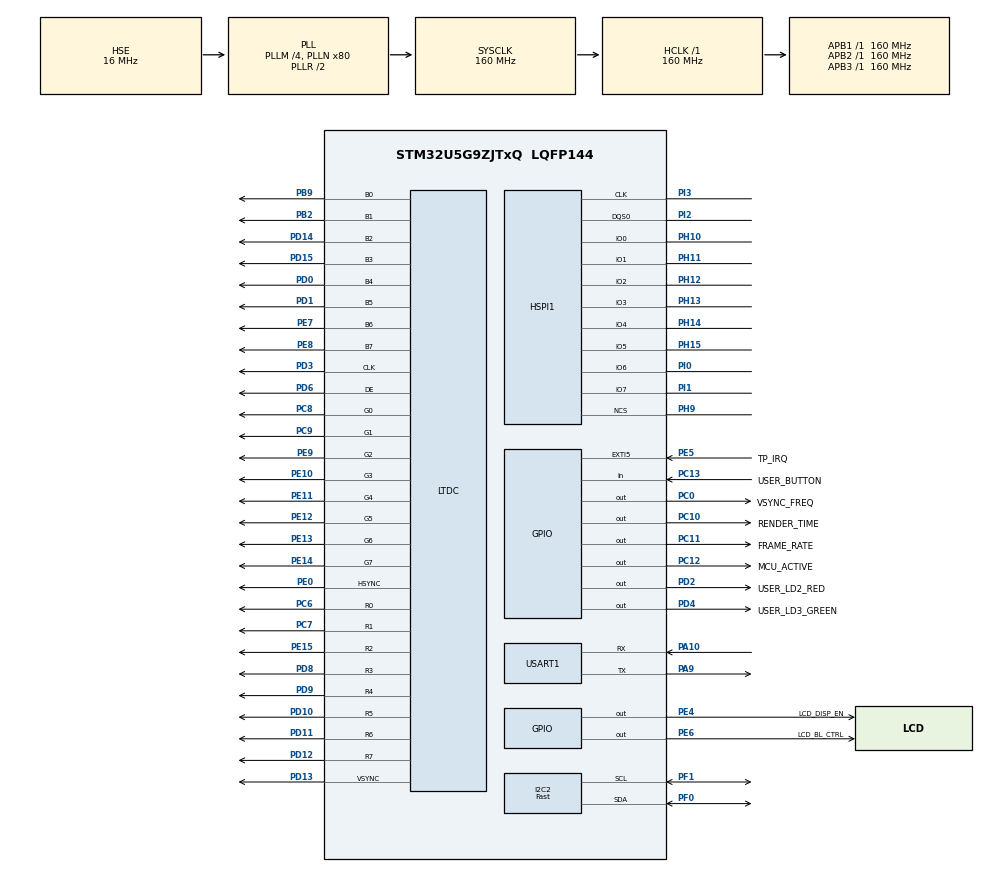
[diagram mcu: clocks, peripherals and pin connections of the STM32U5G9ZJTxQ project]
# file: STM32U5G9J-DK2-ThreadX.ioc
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CORTEX_M33_NS.userName=CORTEX_M33
DCACHE1.DCACHE_Read_Burst_Type=DCACHE_READ_BURST_INCR
DCACHE2.DCACHE_Read_Burst_Type=DCACHE_READ_BURST_INCR
DMA2D.ColorMode=DMA2D_OUTPUT_RGB888
DMA2D.Mode=DMA2D_R2M
GPDMA1.DATAALIGNEMENT_GPDMACH0=DMA_DATA_PACK
GPDMA1.DATAHANDLING_GPDMACH0=ENABLE
GPDMA1.DATAHANDLING_GPDMACH1=NONE
GPDMA1.DESTBURSTLENGTH_GPDMACH0=8
GPDMA1.DESTBURSTLENGTH_GPDMACH1=8
GPDMA1.DESTDATAWIDTH_GPDMACH0=DMA_DEST_DATAWIDTH_WORD
GPDMA1.DESTDATAWIDTH_GPDMACH1=DMA_DEST_DATAWIDTH_WORD
GPDMA1.DESTINC_GPDMACH1=DMA_DINC_INCREMENTED
GPDMA1.DIRECTION_GPDMACH0=DMA_MEMORY_TO_PERIPH
GPDMA1.IPHANDLE_GPDMACH0-SIMPLEREQUEST_GPDMACH0=__NULL
GPDMA1.IPHANDLE_GPDMACH1-SIMPLEREQUEST_GPDMACH1=__NULL
GPDMA1.PRIORITY_GPDMACH0=DMA_HIGH_PRIORITY
GPDMA1.PRIORITY_GPDMACH1=DMA_HIGH_PRIORITY
GPDMA1.REQUEST_GPDMACH0=GPDMA1_REQUEST_JPEG_RX
GPDMA1.REQUEST_GPDMACH1=GPDMA1_REQUEST_JPEG_TX
GPDMA1.SRCBURSTLENGTH_GPDMACH0=8
GPDMA1.SRCBURSTLENGTH_GPDMACH1=8
GPDMA1.SRCDATAWIDTH_GPDMACH1=DMA_SRC_DATAWIDTH_WORD
GPDMA1.SRCINC_GPDMACH0=DMA_SINC_INCREMENTED
GPDMA1.TRANSFERALLOCATEDPORTDEST_GPDMACH1=DMA_DEST_ALLOCATED_PORT1
GPDMA1.TRANSFERALLOCATEDPORTSRC_GPDMACH0=DMA_SRC_ALLOCATED_PORT1
HSPI1.ChipSelectHighTimeCycle=2
HSPI1.ClockPrescaler=0
HSPI1.DeviceType=SPI_DEVICE_FLASH
HSPI1.FifoThresholdByte=4
HSPI1.MemorySize=HAL_XSPI_SIZE_1GB
HSPI1.MemoryType=HAL_XSPI_MEMTYPE_MACRONIX
I2C2.I2C_Speed_Mode=I2C_Fast
I2C2.Timing=0x00F07BFF
JPEG.JPEG_RGB_FORMAT=JPEG_RGB565
JPEG.USE_JPEG_ENCODER=0
LTDC.ActiveW=800
LTDC.Alpha_L0=255
LTDC.FBStartAdress_L0=0x20000000
LTDC.HBP=8
LTDC.HFP=8
LTDC.HSync=5
LTDC.ImageHeight_L0=480
LTDC.ImageWidth_L0=800
LTDC.Layers=0
LTDC.PixelFormat_L0=LTDC_PIXEL_FORMAT_RGB565
LTDC.VBP=8
LTDC.VFP=14
LTDC.VSync=5
LTDC.WindowX1_L0=800
LTDC.WindowY1_L0=480
Mcu.Family=STM32U5
Mcu.Name=STM32U5G9ZJTxQ
Mcu.Package=LQFP144
NVIC.DMA2D_IRQn=true\:0\:0\:false\:false\:true\:true\:true\:true
NVIC.EXTI5_IRQn=true\:0\:0\:false\:false\:true\:true\:true\:true
NVIC.GPDMA1_Channel0_IRQn=true\:0\:0\:false\:false\:true\:false\:true\:true
NVIC.GPDMA1_Channel1_IRQn=true\:0\:0\:false\:false\:true\:false\:true\:true
NVIC.GPU2D_ER_IRQn=true\:0\:0\:false\:false\:true\:true\:true\:true
NVIC.GPU2D_IRQn=true\:0\:0\:false\:false\:true\:true\:true\:true
NVIC.HSPI1_IRQn=true\:0\:0\:false\:false\:true\:true\:true\:true
NVIC.JPEG_IRQn=true\:7\:0\:true\:false\:true\:true\:true\:true
NVIC.LTDC_ER_IRQn=true\:0\:0\:false\:false\:true\:true\:true\:true
NVIC.LTDC_IRQn=true\:0\:0\:false\:false\:true\:true\:true\:true
NVIC.PriorityGroup=NVIC_PRIORITYGROUP_4
NVIC.TIM6_IRQn=true\:15\:0\:true\:false\:true\:false\:true\:true
NVIC.TimeBase=TIM6_IRQn
NVIC.TimeBaseIP=TIM6
PA10.Mode=Asynchronous
PA10.Signal=USART1_RX
PA9.Mode=Asynchronous
PA9.Signal=USART1_TX
PB2.Mode=RGB888
PB2.Signal=LTDC_B1
PB9.Mode=RGB888
PB9.Signal=LTDC_B0
PC0.GPIO_Label=VSYNC_FREQ
PC0.GPIO_Speed=GPIO_SPEED_FREQ_MEDIUM
PC0.Signal=GPIO_Output
PC10.GPIO_Label=RENDER_TIME
PC10.GPIO_Speed=GPIO_SPEED_FREQ_MEDIUM
PC10.Signal=GPIO_Output
PC11.GPIO_Label=FRAME_RATE
PC11.GPIO_Speed=GPIO_SPEED_FREQ_MEDIUM
PC11.Signal=GPIO_Output
PC12.GPIO_Label=MCU_ACTIVE
PC12.GPIO_Speed=GPIO_SPEED_FREQ_MEDIUM
PC12.Signal=GPIO_Output
PC13.GPIO_Label=USER_BUTTON
PC13.GPIO_PuPd=GPIO_PULLDOWN
PC13.Signal=GPIO_Input
PC6.Mode=RGB888
PC6.Signal=LTDC_R0
PC7.Mode=RGB888
PC7.Signal=LTDC_R1
PC8.Mode=RGB888
PC8.Signal=LTDC_G0
PC9.Mode=RGB888
PC9.Signal=LTDC_G1
PD0.Mode=RGB888
PD0.Signal=LTDC_B4
PD1.Mode=RGB888
PD1.Signal=LTDC_B5
PD10.Mode=RGB888
PD10.Signal=LTDC_R5
PD11.Mode=RGB888
PD11.Signal=LTDC_R6
PD12.Mode=RGB888
PD12.Signal=LTDC_R7
PD13.GPIO_Mode=GPIO_MODE_AF_PP
PD13.GPIO_Speed=GPIO_SPEED_FREQ_LOW
PD13.Mode=RGB888
PD13.Signal=LTDC_VSYNC
PD14.Mode=RGB888
PD14.Signal=LTDC_B2
PD15.Mode=RGB888
PD15.Signal=LTDC_B3
PD2.GPIO_Label=USER_LD2_RED
PD2.GPIO_ModeDefaultOutputPP=GPIO_MODE_OUTPUT_OD
PD2.GPIO_PuPd=GPIO_NOPULL
PD2.GPIO_Speed=GPIO_SPEED_FREQ_MEDIUM
PD2.PinState=GPIO_PIN_SET
PD2.Signal=GPIO_Output
PD3.GPIO_Speed=GPIO_SPEED_FREQ_LOW
PD3.Mode=RGB888
PD3.Signal=LTDC_CLK
PD4.GPIO_Label=USER_LD3_GREEN
PD4.GPIO_ModeDefaultOutputPP=GPIO_MODE_OUTPUT_OD
PD4.GPIO_PuPd=GPIO_NOPULL
PD4.GPIO_Speed=GPIO_SPEED_FREQ_MEDIUM
PD4.PinState=GPIO_PIN_SET
PD4.Signal=GPIO_Output
PD6.Mode=RGB888
PD6.Signal=LTDC_DE
PD8.Mode=RGB888
PD8.Signal=LTDC_R3
PD9.Mode=RGB888
PD9.Signal=LTDC_R4
PE0.GPIO_Speed=GPIO_SPEED_FREQ_LOW
PE0.Mode=RGB888
PE0.Signal=LTDC_HSYNC
PE10.Mode=RGB888
PE10.Signal=LTDC_G3
PE11.Mode=RGB888
PE11.Signal=LTDC_G4
PE12.Mode=RGB888
PE12.Signal=LTDC_G5
PE13.Mode=RGB888
PE13.Signal=LTDC_G6
PE14.Mode=RGB888
PE14.Signal=LTDC_G7
PE15.Mode=RGB888
PE15.Signal=LTDC_R2
PE4.GPIO_Label=LCD_DISP_EN
PE4.PinState=GPIO_PIN_SET
PE4.Signal=GPIO_Output
PE5.GPIO_Label=TP_IRQ
PE5.GPIO_ModeDefaultEXTI=GPIO_MODE_IT_FALLING
PE5.GPIO_PuPd=GPIO_PULLUP
PE5.Signal=GPXTI5
PE6.GPIO_Label=LCD_BL_CTRL
PE6.GPIO_ModeDefaultOutputPP=GPIO_MODE_OUTPUT_OD
PE6.GPIO_PuPd=GPIO_NOPULL
PE6.PinState=GPIO_PIN_SET
PE6.Signal=GPIO_Output
PE7.Mode=RGB888
PE7.Signal=LTDC_B6
PE8.Mode=RGB888
PE8.Signal=LTDC_B7
PE9.Mode=RGB888
PE9.Signal=LTDC_G2
PF0.Mode=I2C
PF0.Signal=I2C2_SDA
PF1.Mode=I2C
PF1.Signal=I2C2_SCL
PH0-OSC_IN\ (PH0).Mode=HSE-External-Oscillator
PH0-OSC_IN\ (PH0).Signal=RCC_OSC_IN
PH1-OSC_OUT\ (PH1).Mode=HSE-External-Oscillator
PH1-OSC_OUT\ (PH1).Signal=RCC_OSC_OUT
PH10.Mode=octo_mode
PH10.Signal=HSPI1_IO0
PH11.Mode=octo_mode
PH11.Signal=HSPI1_IO1
PH12.Mode=octo_mode
PH12.Signal=HSPI1_IO2
PH13.Mode=octo_mode
PH13.Signal=HSPI1_IO3
PH14.Mode=octo_mode
PH14.Signal=HSPI1_IO4
PH15.Mode=octo_mode
PH15.Signal=HSPI1_IO5
PH9.Mode=octo_mode
PH9.Signal=HSPI1_NCS
PI0.Mode=octo_mode
PI0.Signal=HSPI1_IO6
PI1.Mode=octo_mode
PI1.Signal=HSPI1_IO7
PI2.Mode=octo_mode
PI2.Signal=HSPI1_DQS0
PI3.Mode=octo_mode
PI3.Signal=HSPI1_CLK
PWR.PowerMode=PWR_SMPS_SUPPLY
ProjectManager.HeapSize=0x1000
ProjectManager.StackSize=0x1000
ProjectManager.TargetToolchain=STM32CubeIDE
RCC.ADCFreq_Value=16000000
RCC.AHBFreq_Value=160000000
RCC.APB1Freq_Value=160000000
RCC.APB1TimFreq_Value=160000000
RCC.APB2Freq_Value=160000000
RCC.APB2TimFreq_Value=160000000
RCC.APB3Freq_Value=160000000
RCC.CortexFreq_Value=160000000
RCC.DSICLockSelection=RCC_DSICLKSOURCE_PLL3
RCC.EPOD_VALUE=16000000
RCC.HCLKFreq_Value=160000000
RCC.HSE_VALUE=16000000
RCC.HSI48_VALUE=48000000
RCC.HSI_VALUE=16000000
RCC.HSPICLockSelection=RCC_HSPICLKSOURCE_PLL2
RCC.LSE_VALUE=32768
RCC.LSIDIV_VALUE=32000
RCC.LTDCCLockSelection=RCC_LTDCCLKSOURCE_PLL3
RCC.MSI_VALUE=4000000
RCC.PLL2M=4
RCC.PLL2N=66
RCC.PLL2Source=RCC_PLLSOURCE_HSE
RCC.PLL3M=4
RCC.PLL3N=125
RCC.PLL3P=8
RCC.PLL3R=20
RCC.PLL3Source=RCC_PLLSOURCE_HSE
RCC.PLLDSIIDF=DSI_PLL_IN_DIV4
RCC.PLLDSINDIV=125
RCC.PLLDSIODF=DSI_PLL_OUT_DIV2
RCC.PLLM=4
RCC.PLLN=80
RCC.PLLSourceVirtual=RCC_PLLSOURCE_HSE
RCC.SYSCLKFreq_VALUE=160000000
RCC.SYSCLKSource=RCC_SYSCLKSOURCE_PLLCLK
RCC.VCOOutputFreq_Value=320000000
STMicroelectronics.X-CUBE-FREERTOS.1.0.1.configENABLE_FPU=1
STMicroelectronics.X-CUBE-FREERTOS.1.0.1.configTOTAL_HEAP_SIZE=80000
STMicroelectronics.X-CUBE-FREERTOS.1.0.1.configUSE_APPLICATION_TASK_TAG=1
STMicroelectronics.X-CUBE-FREERTOS.1.0.1.configUSE_IDLE_HOOK=1
STMicroelectronics.X-CUBE-TOUCHGFX.4.23.2.tgfx_buffering_strategy=Double
STMicroelectronics.X-CUBE-TOUCHGFX.4.23.2.tgfx_display_interface=disp_ltdc
STMicroelectronics.X-CUBE-TOUCHGFX.4.23.2.tgfx_hardware_accelerator=dma_2d
STMicroelectronics.X-CUBE-TOUCHGFX.4.23.2.tgfx_nemap_accelerator=gpu2d_enabled
STMicroelectronics.X-CUBE-TOUCHGFX.4.23.2.tgfx_oswrapper=ThreadX
STMicroelectronics.X-CUBE-TOUCHGFX.4.23.2.tgfx_vector_fonts=Enabled
STMicroelectronics.X-CUBE-TOUCHGFX.4.23.2.tgfx_vector_rendering=Hardware
STMicroelectronics.X-CUBE-TOUCHGFX.4.23.2.tgfx_video=Hardware
STMicroelectronics.X-CUBE-TOUCHGFX.4.23.2.tgfx_video_height=480
STMicroelectronics.X-CUBE-TOUCHGFX.4.23.2.tgfx_video_width=800
STMicroelectronics.X-CUBE-TOUCHGFX.4.23.2.tgfx_vsync=vsync_ltdc
STMicroelectronics.X-CUBE-TOUCHGFX.4.23.2_IsPackSelfContextualization=true
USART1.VirtualMode-Asynchronous=VM_ASYNC
VP_CRC_VS_CRC.Mode=CRC_Activate
VP_DCACHE1_VS_DCACHE.Mode=DCACHE_Activate
VP_DCACHE2_VS_DCACHE.Mode=DCACHE_Activate
VP_DMA2D_VS_DMA2D.Mode=DMA2D_Activate
VP_GPDMA1_VS_GPDMACH0.Mode=SIMPLEREQUEST_GPDMACH0
VP_GPDMA1_VS_GPDMACH1.Mode=SIMPLEREQUEST_GPDMACH1
VP_GPU2D_VS_GPU2D.Mode=GPU2D_Activate
VP_ICACHE_VS_ICACHE.Mode=DirectMappedCache
VP_JPEG_VS_JPEG.Mode=JPEG_Activate
VP_LPBAMQUEUE_VS_QUEUE.Mode=QUEUEMODE
VP_LPBAM_VS_SIG1.Mode=SmartRun
VP_LPBAM_VS_SIG4.Mode=LPDMA1
VP_MEMORYMAP_VS_MEMORYMAP.Mode=CurAppReg
VP_PWR_VS_DBSignals.Mode=DisableDeadBatterySignals
VP_PWR_VS_LPOM.Mode=PowerOptimisation
VP_PWR_VS_SECSignals.Mode=Security/Privilege
VP_SYS_VS_tim6.Mode=TIM6
board=custom

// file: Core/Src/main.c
/* USER CODE BEGIN Header */
/**
  ******************************************************************************
  * @file           : main.c
  * @brief          : Main program body
  ******************************************************************************
  * @attention
  *
  * Copyright (c) 2025 STMicroelectronics.
  * All rights reserved.
  *
  * This software is licensed under terms that can be found in the LICENSE file
  * in the root directory of this software component.
  * If no LICENSE file comes with this software, it is provided AS-IS.
  *
  ******************************************************************************
  */
/* USER CODE END Header */
#include "main.h"
#include "jpeg_utils_conf.h"

/* USER CODE BEGIN Includes */
#include "lvgl_port.h"
#include "lvgl/lvgl.h"
#include "lvgl/demos/lv_demos.h"
#include "lvgl/examples/lv_examples.h"
#include "main_scr.h"

/* USER CODE END Includes */

CRC_HandleTypeDef hcrc;

DCACHE_HandleTypeDef hdcache1;
DCACHE_HandleTypeDef hdcache2;

DMA2D_HandleTypeDef hdma2d;

GPU2D_HandleTypeDef hgpu2d;

XSPI_HandleTypeDef hxspi1;

I2C_HandleTypeDef hi2c2;

JPEG_HandleTypeDef hjpeg;
DMA_HandleTypeDef handle_GPDMA1_Channel1;
DMA_HandleTypeDef handle_GPDMA1_Channel0;

LTDC_HandleTypeDef hltdc;

UART_HandleTypeDef huart1;

void SystemClock_Config(void);
static void SystemPower_Config(void);
static void MX_GPIO_Init(void);
static void MX_GPDMA1_Init(void);
static void MX_ICACHE_Init(void);
static void MX_DCACHE1_Init(void);
static void MX_DCACHE2_Init(void);
static void MX_CRC_Init(void);
static void MX_LTDC_Init(void);
static void MX_DMA2D_Init(void);
static void MX_GPU2D_Init(void);
static void MX_HSPI1_Init(void);
static void MX_I2C2_Init(void);
static void MX_JPEG_Init(void);
static void MX_USART1_UART_Init(void);

int main(void)
{

  /* MCU Configuration--------------------------------------------------------*/

  /* Reset of all peripherals, Initializes the Flash interface and the Systick. */
  HAL_Init();

  /* Configure the System Power */
  SystemPower_Config();

  /* Configure the system clock */
  SystemClock_Config();

  /* Initialize all configured peripherals */
  MX_GPIO_Init();
  MX_GPDMA1_Init();
  MX_ICACHE_Init();
  MX_DCACHE1_Init();
  MX_DCACHE2_Init();
  MX_CRC_Init();
  MX_LTDC_Init();
  MX_DMA2D_Init();
  MX_GPU2D_Init();
  MX_HSPI1_Init();
  MX_I2C2_Init();
  MX_JPEG_Init();
  MX_USART1_UART_Init();

  /* USER CODE BEGIN 2 */

  lvgl_port_init();
  lv_obj_t * out = main_screen_start();
  lv_scr_load(out);

  /* USER CODE END 2 */

  /* Infinite loop */
  while (1)
  {

    /* USER CODE BEGIN 3 */
	  lv_timer_handler();
	  HAL_Delay(1);
  }
  /* USER CODE END 3 */
}

void SystemClock_Config(void)
{
  RCC_OscInitTypeDef RCC_OscInitStruct = {0};
  RCC_ClkInitTypeDef RCC_ClkInitStruct = {0};

  /** Configure the main internal regulator output voltage
  */
  if (HAL_PWREx_ControlVoltageScaling(PWR_REGULATOR_VOLTAGE_SCALE1) != HAL_OK)
  {
    Error_Handler();
  }

  /** Initializes the CPU, AHB and APB buses clocks
  */
  RCC_OscInitStruct.OscillatorType = RCC_OSCILLATORTYPE_HSE;
  RCC_OscInitStruct.HSEState = RCC_HSE_ON;
  RCC_OscInitStruct.PLL.PLLState = RCC_PLL_ON;
  RCC_OscInitStruct.PLL.PLLSource = RCC_PLLSOURCE_HSE;
  RCC_OscInitStruct.PLL.PLLMBOOST = RCC_PLLMBOOST_DIV1;
  RCC_OscInitStruct.PLL.PLLM = 4;
  RCC_OscInitStruct.PLL.PLLN = 80;
  RCC_OscInitStruct.PLL.PLLP = 2;
  RCC_OscInitStruct.PLL.PLLQ = 2;
  RCC_OscInitStruct.PLL.PLLR = 2;
  RCC_OscInitStruct.PLL.PLLRGE = RCC_PLLVCIRANGE_0;
  RCC_OscInitStruct.PLL.PLLFRACN = 0;
  if (HAL_RCC_OscConfig(&RCC_OscInitStruct) != HAL_OK)
  {
    Error_Handler();
  }

  /** Initializes the CPU, AHB and APB buses clocks
  */
  RCC_ClkInitStruct.ClockType = RCC_CLOCKTYPE_HCLK|RCC_CLOCKTYPE_SYSCLK
                              |RCC_CLOCKTYPE_PCLK1|RCC_CLOCKTYPE_PCLK2
                              |RCC_CLOCKTYPE_PCLK3;
  RCC_ClkInitStruct.SYSCLKSource = RCC_SYSCLKSOURCE_PLLCLK;
  RCC_ClkInitStruct.AHBCLKDivider = RCC_SYSCLK_DIV1;
  RCC_ClkInitStruct.APB1CLKDivider = RCC_HCLK_DIV1;
  RCC_ClkInitStruct.APB2CLKDivider = RCC_HCLK_DIV1;
  RCC_ClkInitStruct.APB3CLKDivider = RCC_HCLK_DIV1;

  if (HAL_RCC_ClockConfig(&RCC_ClkInitStruct, FLASH_LATENCY_4) != HAL_OK)
  {
    Error_Handler();
  }
}

/**
  * @brief Power Configuration
  * @retval None
  */
static void SystemPower_Config(void)
{

  /*
   * Disable the internal Pull-Up in Dead Battery pins of UCPD peripheral
   */
  HAL_PWREx_DisableUCPDDeadBattery();

  /*
   * Switch to SMPS regulator instead of LDO
   */
  if (HAL_PWREx_ConfigSupply(PWR_SMPS_SUPPLY) != HAL_OK)
  {
    Error_Handler();
  }
}

static void MX_CRC_Init(void)
{

  hcrc.Instance = CRC;
  hcrc.Init.DefaultPolynomialUse = DEFAULT_POLYNOMIAL_ENABLE;
  hcrc.Init.DefaultInitValueUse = DEFAULT_INIT_VALUE_ENABLE;
  hcrc.Init.InputDataInversionMode = CRC_INPUTDATA_INVERSION_NONE;
  hcrc.Init.OutputDataInversionMode = CRC_OUTPUTDATA_INVERSION_DISABLE;
  hcrc.InputDataFormat = CRC_INPUTDATA_FORMAT_BYTES;
  if (HAL_CRC_Init(&hcrc) != HAL_OK)
  {
    Error_Handler();
  }

}

static void MX_DCACHE1_Init(void)
{

  hdcache1.Instance = DCACHE1;
  hdcache1.Init.ReadBurstType = DCACHE_READ_BURST_INCR;
  if (HAL_DCACHE_Init(&hdcache1) != HAL_OK)
  {
    Error_Handler();
  }

}

static void MX_DCACHE2_Init(void)
{

  hdcache2.Instance = DCACHE2;
  hdcache2.Init.ReadBurstType = DCACHE_READ_BURST_INCR;
  if (HAL_DCACHE_Init(&hdcache2) != HAL_OK)
  {
    Error_Handler();
  }
   __HAL_RCC_SYSCFG_CLK_ENABLE();
   HAL_SYSCFG_DisableSRAMCached();

}

static void MX_DMA2D_Init(void)
{

  hdma2d.Instance = DMA2D;
  hdma2d.Init.Mode = DMA2D_R2M;
  hdma2d.Init.ColorMode = DMA2D_OUTPUT_RGB888;
  hdma2d.Init.OutputOffset = 0;
  hdma2d.Init.BytesSwap = DMA2D_BYTES_REGULAR;
  hdma2d.Init.LineOffsetMode = DMA2D_LOM_PIXELS;
  if (HAL_DMA2D_Init(&hdma2d) != HAL_OK)
  {
    Error_Handler();
  }

}

static void MX_GPDMA1_Init(void)
{

  /* Peripheral clock enable */
  __HAL_RCC_GPDMA1_CLK_ENABLE();

  /* GPDMA1 interrupt Init */
    HAL_NVIC_SetPriority(GPDMA1_Channel0_IRQn, 0, 0);
    HAL_NVIC_EnableIRQ(GPDMA1_Channel0_IRQn);
    HAL_NVIC_SetPriority(GPDMA1_Channel1_IRQn, 0, 0);
    HAL_NVIC_EnableIRQ(GPDMA1_Channel1_IRQn);

}

static void MX_GPU2D_Init(void)
{

  hgpu2d.Instance = GPU2D;
  if (HAL_GPU2D_Init(&hgpu2d) != HAL_OK)
  {
    Error_Handler();
  }

}

static void MX_HSPI1_Init(void)
{

  /* HSPI1 parameter configuration*/
  hxspi1.Instance = HSPI1;
  hxspi1.Init.FifoThresholdByte = 4;
  hxspi1.Init.MemoryMode = HAL_XSPI_SINGLE_MEM;
  hxspi1.Init.MemoryType = HAL_XSPI_MEMTYPE_MACRONIX;
  hxspi1.Init.MemorySize = HAL_XSPI_SIZE_1GB;
  hxspi1.Init.ChipSelectHighTimeCycle = 2;
  hxspi1.Init.FreeRunningClock = HAL_XSPI_FREERUNCLK_DISABLE;
  hxspi1.Init.ClockMode = HAL_XSPI_CLOCK_MODE_0;
  hxspi1.Init.WrapSize = HAL_XSPI_WRAP_NOT_SUPPORTED;
  hxspi1.Init.ClockPrescaler = 0;
  hxspi1.Init.SampleShifting = HAL_XSPI_SAMPLE_SHIFT_NONE;
  hxspi1.Init.DelayHoldQuarterCycle = HAL_XSPI_DHQC_DISABLE;
  hxspi1.Init.ChipSelectBoundary = HAL_XSPI_BONDARYOF_NONE;
  hxspi1.Init.MaxTran = 0;
  hxspi1.Init.Refresh = 0;
  if (HAL_XSPI_Init(&hxspi1) != HAL_OK)
  {
    Error_Handler();
  }

}

static void MX_I2C2_Init(void)
{

  hi2c2.Instance = I2C2;
  hi2c2.Init.Timing = 0x00F07BFF;
  hi2c2.Init.OwnAddress1 = 0;
  hi2c2.Init.AddressingMode = I2C_ADDRESSINGMODE_7BIT;
  hi2c2.Init.DualAddressMode = I2C_DUALADDRESS_DISABLE;
  hi2c2.Init.OwnAddress2 = 0;
  hi2c2.Init.OwnAddress2Masks = I2C_OA2_NOMASK;
  hi2c2.Init.GeneralCallMode = I2C_GENERALCALL_DISABLE;
  hi2c2.Init.NoStretchMode = I2C_NOSTRETCH_DISABLE;
  if (HAL_I2C_Init(&hi2c2) != HAL_OK)
  {
    Error_Handler();
  }

  /** Configure Analogue filter
  */
  if (HAL_I2CEx_ConfigAnalogFilter(&hi2c2, I2C_ANALOGFILTER_ENABLE) != HAL_OK)
  {
    Error_Handler();
  }

  /** Configure Digital filter
  */
  if (HAL_I2CEx_ConfigDigitalFilter(&hi2c2, 0) != HAL_OK)
  {
    Error_Handler();
  }

}

static void MX_ICACHE_Init(void)
{

  /** Enable instruction cache in 1-way (direct mapped cache)
  */
  if (HAL_ICACHE_ConfigAssociativityMode(ICACHE_1WAY) != HAL_OK)
  {
    Error_Handler();
  }
  if (HAL_ICACHE_Enable() != HAL_OK)
  {
    Error_Handler();
  }

}

static void MX_JPEG_Init(void)
{

  hjpeg.Instance = JPEG;
  if (HAL_JPEG_Init(&hjpeg) != HAL_OK)
  {
    Error_Handler();
  }

}

static void MX_LTDC_Init(void)
{

  LTDC_LayerCfgTypeDef pLayerCfg = {0};

  hltdc.Instance = LTDC;
  hltdc.Init.HSPolarity = LTDC_HSPOLARITY_AL;
  hltdc.Init.VSPolarity = LTDC_VSPOLARITY_AL;
  hltdc.Init.DEPolarity = LTDC_DEPOLARITY_AL;
  hltdc.Init.PCPolarity = LTDC_PCPOLARITY_IPC;
  hltdc.Init.HorizontalSync = 4;
  hltdc.Init.VerticalSync = 4;
  hltdc.Init.AccumulatedHBP = 12;
  hltdc.Init.AccumulatedVBP = 12;
  hltdc.Init.AccumulatedActiveW = 812;
  hltdc.Init.AccumulatedActiveH = 492;
  hltdc.Init.TotalWidth = 820;
  hltdc.Init.TotalHeigh = 506;
  hltdc.Init.Backcolor.Blue = 0;
  hltdc.Init.Backcolor.Green = 0;
  hltdc.Init.Backcolor.Red = 0;
  if (HAL_LTDC_Init(&hltdc) != HAL_OK)
  {
    Error_Handler();
  }
  pLayerCfg.WindowX0 = 0;
  pLayerCfg.WindowX1 = 800;
  pLayerCfg.WindowY0 = 0;
  pLayerCfg.WindowY1 = 480;
  pLayerCfg.PixelFormat = LTDC_PIXEL_FORMAT_RGB565;
  pLayerCfg.Alpha = 255;
  pLayerCfg.Alpha0 = 0;
  pLayerCfg.BlendingFactor1 = LTDC_BLENDING_FACTOR1_CA;
  pLayerCfg.BlendingFactor2 = LTDC_BLENDING_FACTOR2_CA;
  pLayerCfg.FBStartAdress = 0x20000000;
  pLayerCfg.ImageWidth = 800;
  pLayerCfg.ImageHeight = 480;
  pLayerCfg.Backcolor.Blue = 0;
  pLayerCfg.Backcolor.Green = 0;
  pLayerCfg.Backcolor.Red = 0;
  if (HAL_LTDC_ConfigLayer(&hltdc, &pLayerCfg, 0) != HAL_OK)
  {
    Error_Handler();
  }

}

static void MX_USART1_UART_Init(void)
{

  huart1.Instance = USART1;
  huart1.Init.BaudRate = 115200;
  huart1.Init.WordLength = UART_WORDLENGTH_8B;
  huart1.Init.StopBits = UART_STOPBITS_1;
  huart1.Init.Parity = UART_PARITY_NONE;
  huart1.Init.Mode = UART_MODE_TX_RX;
  huart1.Init.HwFlowCtl = UART_HWCONTROL_NONE;
  huart1.Init.OverSampling = UART_OVERSAMPLING_16;
  huart1.Init.OneBitSampling = UART_ONE_BIT_SAMPLE_DISABLE;
  huart1.Init.ClockPrescaler = UART_PRESCALER_DIV1;
  huart1.AdvancedInit.AdvFeatureInit = UART_ADVFEATURE_NO_INIT;
  if (HAL_UART_Init(&huart1) != HAL_OK)
  {
    Error_Handler();
  }
  if (HAL_UARTEx_SetTxFifoThreshold(&huart1, UART_TXFIFO_THRESHOLD_1_8) != HAL_OK)
  {
    Error_Handler();
  }
  if (HAL_UARTEx_SetRxFifoThreshold(&huart1, UART_RXFIFO_THRESHOLD_1_8) != HAL_OK)
  {
    Error_Handler();
  }
  if (HAL_UARTEx_DisableFifoMode(&huart1) != HAL_OK)
  {
    Error_Handler();
  }

}

static void MX_GPIO_Init(void)
{
  GPIO_InitTypeDef GPIO_InitStruct = {0};

  /* GPIO Ports Clock Enable */
  __HAL_RCC_GPIOE_CLK_ENABLE();
  __HAL_RCC_GPIOC_CLK_ENABLE();
  __HAL_RCC_GPIOF_CLK_ENABLE();
  __HAL_RCC_GPIOH_CLK_ENABLE();
  __HAL_RCC_GPIOB_CLK_ENABLE();
  __HAL_RCC_GPIOD_CLK_ENABLE();
  __HAL_RCC_GPIOI_CLK_ENABLE();
  __HAL_RCC_GPIOA_CLK_ENABLE();

  /*Configure GPIO pin Output Level */
  HAL_GPIO_WritePin(GPIOE, LCD_DISP_EN_Pin|LCD_BL_CTRL_Pin, GPIO_PIN_SET);

  /*Configure GPIO pin Output Level */
  HAL_GPIO_WritePin(GPIOC, VSYNC_FREQ_Pin|RENDER_TIME_Pin|FRAME_RATE_Pin|MCU_ACTIVE_Pin, GPIO_PIN_RESET);

  /*Configure GPIO pin Output Level */
  HAL_GPIO_WritePin(GPIOD, USER_LD2_RED_Pin|USER_LD3_GREEN_Pin, GPIO_PIN_SET);

  /*Configure GPIO pin : LCD_DISP_EN_Pin */
  GPIO_InitStruct.Pin = LCD_DISP_EN_Pin;
  GPIO_InitStruct.Mode = GPIO_MODE_OUTPUT_PP;
  GPIO_InitStruct.Pull = GPIO_NOPULL;
  GPIO_InitStruct.Speed = GPIO_SPEED_FREQ_LOW;
  HAL_GPIO_Init(LCD_DISP_EN_GPIO_Port, &GPIO_InitStruct);

  /*Configure GPIO pin : TP_IRQ_Pin */
  GPIO_InitStruct.Pin = TP_IRQ_Pin;
  GPIO_InitStruct.Mode = GPIO_MODE_IT_FALLING;
  GPIO_InitStruct.Pull = GPIO_PULLUP;
  HAL_GPIO_Init(TP_IRQ_GPIO_Port, &GPIO_InitStruct);

  /*Configure GPIO pin : LCD_BL_CTRL_Pin */
  GPIO_InitStruct.Pin = LCD_BL_CTRL_Pin;
  GPIO_InitStruct.Mode = GPIO_MODE_OUTPUT_OD;
  GPIO_InitStruct.Pull = GPIO_NOPULL;
  GPIO_InitStruct.Speed = GPIO_SPEED_FREQ_LOW;
  HAL_GPIO_Init(LCD_BL_CTRL_GPIO_Port, &GPIO_InitStruct);

  /*Configure GPIO pin : USER_BUTTON_Pin */
  GPIO_InitStruct.Pin = USER_BUTTON_Pin;
  GPIO_InitStruct.Mode = GPIO_MODE_INPUT;
  GPIO_InitStruct.Pull = GPIO_PULLDOWN;
  HAL_GPIO_Init(USER_BUTTON_GPIO_Port, &GPIO_InitStruct);

  /*Configure GPIO pins : VSYNC_FREQ_Pin RENDER_TIME_Pin FRAME_RATE_Pin MCU_ACTIVE_Pin */
  GPIO_InitStruct.Pin = VSYNC_FREQ_Pin|RENDER_TIME_Pin|FRAME_RATE_Pin|MCU_ACTIVE_Pin;
  GPIO_InitStruct.Mode = GPIO_MODE_OUTPUT_PP;
  GPIO_InitStruct.Pull = GPIO_NOPULL;
  GPIO_InitStruct.Speed = GPIO_SPEED_FREQ_MEDIUM;
  HAL_GPIO_Init(GPIOC, &GPIO_InitStruct);

  /*Configure GPIO pins : USER_LD2_RED_Pin USER_LD3_GREEN_Pin */
  GPIO_InitStruct.Pin = USER_LD2_RED_Pin|USER_LD3_GREEN_Pin;
  GPIO_InitStruct.Mode = GPIO_MODE_OUTPUT_OD;
  GPIO_InitStruct.Pull = GPIO_NOPULL;
  GPIO_InitStruct.Speed = GPIO_SPEED_FREQ_MEDIUM;
  HAL_GPIO_Init(GPIOD, &GPIO_InitStruct);

  /* EXTI interrupt init*/
  HAL_NVIC_SetPriority(EXTI5_IRQn, 0, 0);
  HAL_NVIC_EnableIRQ(EXTI5_IRQn);

}

void HAL_TIM_PeriodElapsedCallback(TIM_HandleTypeDef *htim)
{
  if (htim->Instance == TIM6) {
    HAL_IncTick();
  }
}

void Error_Handler(void)
{
  __disable_irq();
  while (1)
  {
  }
}
